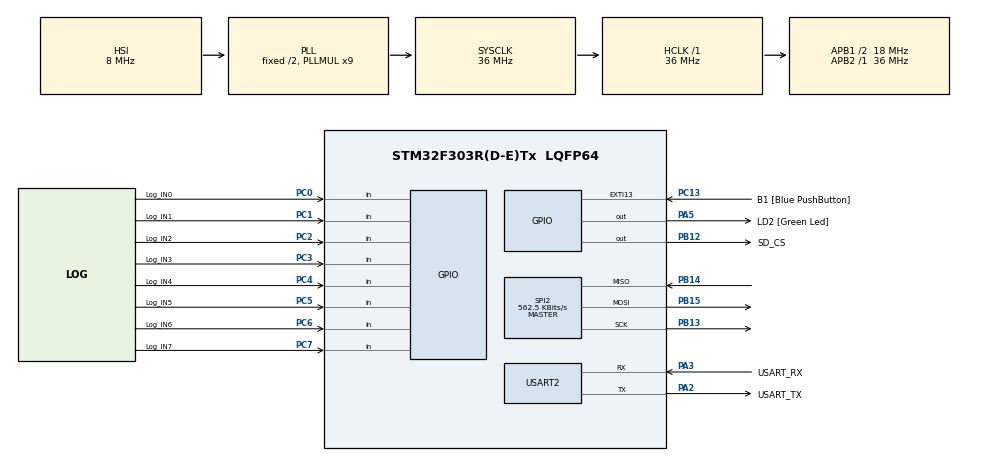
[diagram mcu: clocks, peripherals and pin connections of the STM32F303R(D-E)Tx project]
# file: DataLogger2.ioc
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FATFS._CODE_PAGE=1
FATFS._FS_NORTC=1
FATFS._FS_RPATH=2
FATFS._NORTC_MDAY=6
FATFS._NORTC_MON=11
FATFS._STRF_ENCODE=0
Mcu.Family=STM32F3
Mcu.Name=STM32F303R(D-E)Tx
Mcu.Package=LQFP64
NVIC.PriorityGroup=NVIC_PRIORITYGROUP_0
PA13.GPIO_Label=TMS
PA13.Mode=Serial_Wire
PA13.Signal=SYS_JTMS-SWDIO
PA14.GPIO_Label=TCK
PA14.Mode=Serial_Wire
PA14.Signal=SYS_JTCK-SWCLK
PA2.GPIO_Label=USART_TX
PA2.GPIO_Mode=GPIO_MODE_AF_PP
PA2.GPIO_PuPd=GPIO_NOPULL
PA2.GPIO_Speed=GPIO_SPEED_FREQ_LOW
PA2.Mode=Asynchronous
PA2.Signal=USART2_TX
PA3.GPIO_Label=USART_RX
PA3.GPIO_Mode=GPIO_MODE_AF_PP
PA3.GPIO_PuPd=GPIO_NOPULL
PA3.GPIO_Speed=GPIO_SPEED_FREQ_LOW
PA3.Mode=Asynchronous
PA3.Signal=USART2_RX
PA5.GPIO_Label=LD2 [Green Led]
PA5.GPIO_Mode=GPIO_MODE_OUTPUT_PP
PA5.GPIO_PuPd=GPIO_NOPULL
PA5.GPIO_Speed=GPIO_SPEED_FREQ_LOW
PA5.Signal=GPIO_Output
PB12.GPIO_Label=SD_CS
PB12.GPIO_Speed=GPIO_SPEED_FREQ_LOW
PB12.Signal=GPIO_Output
PB13.Mode=Full_Duplex_Master
PB13.Signal=SPI2_SCK
PB14.Mode=Full_Duplex_Master
PB14.Signal=SPI2_MISO
PB15.Mode=Full_Duplex_Master
PB15.Signal=SPI2_MOSI
PB3.GPIO_Label=SWO
PB3.Signal=SYS_JTDO-TRACESWO
PC0.GPIO_Label=Log_IN0
PC0.Signal=GPIO_Input
PC1.GPIO_Label=Log_IN1
PC1.Signal=GPIO_Input
PC13.GPIO_Label=B1 [Blue PushButton]
PC13.GPIO_ModeDefaultEXTI=GPIO_MODE_IT_FALLING
PC13.Signal=GPXTI13
PC14-OSC32_IN.Signal=RCC_OSC32_IN
PC15-OSC32_OUT.Signal=RCC_OSC32_OUT
PC2.GPIO_Label=Log_IN2
PC2.Signal=GPIO_Input
PC3.GPIO_Label=Log_IN3
PC3.Signal=GPIO_Input
PC4.GPIO_Label=Log_IN4
PC4.Signal=GPIO_Input
PC5.GPIO_Label=Log_IN5
PC5.Signal=GPIO_Input
PC6.GPIO_Label=Log_IN6
PC6.Signal=GPIO_Input
PC7.GPIO_Label=Log_IN7
PC7.Signal=GPIO_Input
PF0-OSC_IN.Signal=RCC_OSC_IN
PF1-OSC_OUT.Signal=RCC_OSC_OUT
ProjectManager.HeapSize=0x200
ProjectManager.StackSize=0x400
ProjectManager.TargetToolchain=STM32CubeIDE
RCC.AHBFreq_Value=36000000
RCC.APB1CLKDivider=RCC_HCLK_DIV2
RCC.APB1Freq_Value=18000000
RCC.APB1TimFreq_Value=36000000
RCC.APB2Freq_Value=36000000
RCC.APB2TimFreq_Value=36000000
RCC.CortexFreq_Value=36000000
RCC.HCLKFreq_Value=36000000
RCC.HSE_VALUE=8000000
RCC.HSI_VALUE=8000000
RCC.LSE_VALUE=32768
RCC.PLLM=8
RCC.PLLMUL=RCC_PLL_MUL9
RCC.PLLN=336
RCC.PLLP=RCC_PLLP_DIV4
RCC.PLLQ=7
RCC.RCC_PLLsource_Clock_Source_FROM_HSE=RCC_HSE_PREDIV_DIV2
RCC.SYSCLKFreq_VALUE=36000000
RCC.SYSCLKSourceVirtual=RCC_SYSCLKSOURCE_PLLCLK
RCC.USBFreq_Value=36000000
SPI2.BaudRatePrescaler=SPI_BAUDRATEPRESCALER_32
SPI2.CalculateBaudRate=562.5 KBits/s
SPI2.DataSize=SPI_DATASIZE_8BIT
SPI2.Direction=SPI_DIRECTION_2LINES
SPI2.Mode=SPI_MODE_MASTER
SPI2.NSSPMode=SPI_NSS_PULSE_DISABLE
SPI2.VirtualType=VM_MASTER
TIM6.Period=0xBBA0
TIM6.Prescaler=0xD
USART2.VirtualMode-Asynchronous=VM_ASYNC
VP_FATFS_VS_Generic.Mode=User_defined
VP_TIM6_VS_ClockSourceINT.Mode=Enable_Timer
board=NUCLEO-F303RE

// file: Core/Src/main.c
/* USER CODE BEGIN Header */
/**
  ******************************************************************************
  * @file           : main.c
  * @brief          : Main program body
  ******************************************************************************
  * @attention
  *
  * Copyright (c) 2025 STMicroelectronics.
  * All rights reserved.
  *
  * This software is licensed under terms that can be found in the LICENSE file
  * in the root directory of this software component.
  * If no LICENSE file comes with this software, it is provided AS-IS.
  *
  ******************************************************************************
  */
/* USER CODE END Header */
#include "main.h"
#include "fatfs.h"
#include "spi.h"
#include "tim.h"
#include "usart.h"
#include "gpio.h"

/* USER CODE BEGIN Includes */
#include "logger.h"
/* USER CODE END Includes */

void SystemClock_Config(void);

int main(void)
{

  /* MCU Configuration--------------------------------------------------------*/

  /* Reset of all peripherals, Initializes the Flash interface and the Systick. */
  HAL_Init();

  /* Configure the system clock */
  SystemClock_Config();

  /* Initialize all configured peripherals */
  MX_GPIO_Init();
  MX_SPI2_Init();
  MX_TIM6_Init();
  MX_USART2_UART_Init();
  MX_FATFS_Init();
  /* USER CODE BEGIN 2 */
  /* ініціалізація логера; у разі помилки – перехід у Error_Handler() */
  if (Logger_Init() != FR_OK)
  {
    Error_Handler();
  }
  /* USER CODE END 2 */

  /* Infinite loop */
  /* USER CODE BEGIN WHILE */
  while (1)
  {
	    /* періодичний виклик алгоритму логування */
	    Logger_Task();
    /* USER CODE END WHILE */

  }
}

void SystemClock_Config(void)
{
  RCC_OscInitTypeDef RCC_OscInitStruct = {0};
  RCC_ClkInitTypeDef RCC_ClkInitStruct = {0};
  RCC_PeriphCLKInitTypeDef PeriphClkInit = {0};

  /** Initializes the RCC Oscillators according to the specified parameters
  * in the RCC_OscInitTypeDef structure.
  */
  RCC_OscInitStruct.OscillatorType = RCC_OSCILLATORTYPE_HSI;
  RCC_OscInitStruct.HSIState = RCC_HSI_ON;
  RCC_OscInitStruct.HSICalibrationValue = RCC_HSICALIBRATION_DEFAULT;
  RCC_OscInitStruct.PLL.PLLState = RCC_PLL_ON;
  RCC_OscInitStruct.PLL.PLLSource = RCC_PLLSOURCE_HSI;
  RCC_OscInitStruct.PLL.PLLMUL = RCC_PLL_MUL9;
  RCC_OscInitStruct.PLL.PREDIV = RCC_PREDIV_DIV1;
  if (HAL_RCC_OscConfig(&RCC_OscInitStruct) != HAL_OK)
  {
    Error_Handler();
  }

  /** Initializes the CPU, AHB and APB buses clocks
  */
  RCC_ClkInitStruct.ClockType = RCC_CLOCKTYPE_HCLK|RCC_CLOCKTYPE_SYSCLK
                              |RCC_CLOCKTYPE_PCLK1|RCC_CLOCKTYPE_PCLK2;
  RCC_ClkInitStruct.SYSCLKSource = RCC_SYSCLKSOURCE_PLLCLK;
  RCC_ClkInitStruct.AHBCLKDivider = RCC_SYSCLK_DIV1;
  RCC_ClkInitStruct.APB1CLKDivider = RCC_HCLK_DIV2;
  RCC_ClkInitStruct.APB2CLKDivider = RCC_HCLK_DIV1;

  if (HAL_RCC_ClockConfig(&RCC_ClkInitStruct, FLASH_LATENCY_1) != HAL_OK)
  {
    Error_Handler();
  }
  PeriphClkInit.PeriphClockSelection = RCC_PERIPHCLK_USART2;
  PeriphClkInit.Usart2ClockSelection = RCC_USART2CLKSOURCE_PCLK1;
  if (HAL_RCCEx_PeriphCLKConfig(&PeriphClkInit) != HAL_OK)
  {
    Error_Handler();
  }
}

void Error_Handler(void)
{
  __disable_irq();
  while (1)
  {
  }
}
